# VPAC0_COMMON_0_PAR_VPAC_VISS0_S_VBUSP_K3_GLBCE_TOP_CFG_GLBCE register map
Vendor: Texas Instruments
Peripheral module from a debugger description file (folder J7_AHP).
Registers are 32-bit, read-write, reset 0x0 unless marked. A register's access mark holds for its fields unless they carry their own. Offsets are as the file gives them; lines under a group give offsets from that group; [hi:lo] are bit positions; {n}, {i} and the like mark numbered series; 'fields as' and 'values as' point back to an identical list; <NAME> marks a mode.

## VPAC0_COMMON_0_PAR_VPAC_VISS0_S_VBUSP_K3_GLBCE_TOP_CFG_GLBCE (part 1 of 2)
0x328 PAR_VPAC_VISS0__S_VBUSP__K3_GLBCE_TOP__CFG__GLBCE_REGS_GLBCE_WDR_GAMMA_LUT_21 reset 0x1500
  [15:0] VAL — LUT Value
0x32C PAR_VPAC_VISS0__S_VBUSP__K3_GLBCE_TOP__CFG__GLBCE_REGS_GLBCE_WDR_GAMMA_LUT_22 reset 0x1600
  [15:0] VAL — LUT Value
0x330 PAR_VPAC_VISS0__S_VBUSP__K3_GLBCE_TOP__CFG__GLBCE_REGS_GLBCE_WDR_GAMMA_LUT_23 reset 0x1700
  [15:0] VAL — LUT Value
0x334 PAR_VPAC_VISS0__S_VBUSP__K3_GLBCE_TOP__CFG__GLBCE_REGS_GLBCE_WDR_GAMMA_LUT_24 reset 0x1800
  [15:0] VAL — LUT Value
0x338 PAR_VPAC_VISS0__S_VBUSP__K3_GLBCE_TOP__CFG__GLBCE_REGS_GLBCE_WDR_GAMMA_LUT_25 reset 0x1900
  [15:0] VAL — LUT Value
0x33C PAR_VPAC_VISS0__S_VBUSP__K3_GLBCE_TOP__CFG__GLBCE_REGS_GLBCE_WDR_GAMMA_LUT_26 reset 0x1A00
  [15:0] VAL — LUT Value
0x340 PAR_VPAC_VISS0__S_VBUSP__K3_GLBCE_TOP__CFG__GLBCE_REGS_GLBCE_WDR_GAMMA_LUT_27 reset 0x1B00
  [15:0] VAL — LUT Value
0x344 PAR_VPAC_VISS0__S_VBUSP__K3_GLBCE_TOP__CFG__GLBCE_REGS_GLBCE_WDR_GAMMA_LUT_28 reset 0x1C00
  [15:0] VAL — LUT Value
0x348 PAR_VPAC_VISS0__S_VBUSP__K3_GLBCE_TOP__CFG__GLBCE_REGS_GLBCE_WDR_GAMMA_LUT_29 reset 0x1D00
  [15:0] VAL — LUT Value
0x34C PAR_VPAC_VISS0__S_VBUSP__K3_GLBCE_TOP__CFG__GLBCE_REGS_GLBCE_WDR_GAMMA_LUT_30 reset 0x1E00
  [15:0] VAL — LUT Value
0x350 PAR_VPAC_VISS0__S_VBUSP__K3_GLBCE_TOP__CFG__GLBCE_REGS_GLBCE_WDR_GAMMA_LUT_31 reset 0x1F00
  [15:0] VAL — LUT Value
0x354 PAR_VPAC_VISS0__S_VBUSP__K3_GLBCE_TOP__CFG__GLBCE_REGS_GLBCE_WDR_GAMMA_LUT_32 reset 0x2000
  [15:0] VAL — LUT Value
0x358 PAR_VPAC_VISS0__S_VBUSP__K3_GLBCE_TOP__CFG__GLBCE_REGS_GLBCE_WDR_GAMMA_LUT_33 reset 0x2100
  [15:0] VAL — LUT Value
0x35C PAR_VPAC_VISS0__S_VBUSP__K3_GLBCE_TOP__CFG__GLBCE_REGS_GLBCE_WDR_GAMMA_LUT_34 reset 0x2200
  [15:0] VAL — LUT Value
0x360 PAR_VPAC_VISS0__S_VBUSP__K3_GLBCE_TOP__CFG__GLBCE_REGS_GLBCE_WDR_GAMMA_LUT_35 reset 0x2300
  [15:0] VAL — LUT Value
0x364 PAR_VPAC_VISS0__S_VBUSP__K3_GLBCE_TOP__CFG__GLBCE_REGS_GLBCE_WDR_GAMMA_LUT_36 reset 0x2400
  [15:0] VAL — LUT Value
0x368 PAR_VPAC_VISS0__S_VBUSP__K3_GLBCE_TOP__CFG__GLBCE_REGS_GLBCE_WDR_GAMMA_LUT_37 reset 0x2500
  [15:0] VAL — LUT Value
0x36C PAR_VPAC_VISS0__S_VBUSP__K3_GLBCE_TOP__CFG__GLBCE_REGS_GLBCE_WDR_GAMMA_LUT_38 reset 0x2600
  [15:0] VAL — LUT Value
0x370 PAR_VPAC_VISS0__S_VBUSP__K3_GLBCE_TOP__CFG__GLBCE_REGS_GLBCE_WDR_GAMMA_LUT_39 reset 0x2700
  [15:0] VAL — LUT Value
0x374 PAR_VPAC_VISS0__S_VBUSP__K3_GLBCE_TOP__CFG__GLBCE_REGS_GLBCE_WDR_GAMMA_LUT_40 reset 0x2800
  [15:0] VAL — LUT Value
0x378 PAR_VPAC_VISS0__S_VBUSP__K3_GLBCE_TOP__CFG__GLBCE_REGS_GLBCE_WDR_GAMMA_LUT_41 reset 0x2900
  [15:0] VAL — LUT Value
0x37C PAR_VPAC_VISS0__S_VBUSP__K3_GLBCE_TOP__CFG__GLBCE_REGS_GLBCE_WDR_GAMMA_LUT_42 reset 0x2A00
  [15:0] VAL — LUT Value
0x380 PAR_VPAC_VISS0__S_VBUSP__K3_GLBCE_TOP__CFG__GLBCE_REGS_GLBCE_WDR_GAMMA_LUT_43 reset 0x2B00
  [15:0] VAL — LUT Value
0x384 PAR_VPAC_VISS0__S_VBUSP__K3_GLBCE_TOP__CFG__GLBCE_REGS_GLBCE_WDR_GAMMA_LUT_44 reset 0x2C00
  [15:0] VAL — LUT Value
0x388 PAR_VPAC_VISS0__S_VBUSP__K3_GLBCE_TOP__CFG__GLBCE_REGS_GLBCE_WDR_GAMMA_LUT_45 reset 0x2D00
  [15:0] VAL — LUT Value
0x38C PAR_VPAC_VISS0__S_VBUSP__K3_GLBCE_TOP__CFG__GLBCE_REGS_GLBCE_WDR_GAMMA_LUT_46 reset 0x2E00
  [15:0] VAL — LUT Value
0x390 PAR_VPAC_VISS0__S_VBUSP__K3_GLBCE_TOP__CFG__GLBCE_REGS_GLBCE_WDR_GAMMA_LUT_47 reset 0x2F00
  [15:0] VAL — LUT Value
0x394 PAR_VPAC_VISS0__S_VBUSP__K3_GLBCE_TOP__CFG__GLBCE_REGS_GLBCE_WDR_GAMMA_LUT_48 reset 0x3000
  [15:0] VAL — LUT Value
0x398 PAR_VPAC_VISS0__S_VBUSP__K3_GLBCE_TOP__CFG__GLBCE_REGS_GLBCE_WDR_GAMMA_LUT_49 reset 0x3100
  [15:0] VAL — LUT Value
0x39C PAR_VPAC_VISS0__S_VBUSP__K3_GLBCE_TOP__CFG__GLBCE_REGS_GLBCE_WDR_GAMMA_LUT_50 reset 0x3200
  [15:0] VAL — LUT Value
0x3A0 PAR_VPAC_VISS0__S_VBUSP__K3_GLBCE_TOP__CFG__GLBCE_REGS_GLBCE_WDR_GAMMA_LUT_51 reset 0x3300
  [15:0] VAL — LUT Value
0x3A4 PAR_VPAC_VISS0__S_VBUSP__K3_GLBCE_TOP__CFG__GLBCE_REGS_GLBCE_WDR_GAMMA_LUT_52 reset 0x3400
  [15:0] VAL — LUT Value
0x3A8 PAR_VPAC_VISS0__S_VBUSP__K3_GLBCE_TOP__CFG__GLBCE_REGS_GLBCE_WDR_GAMMA_LUT_53 reset 0x3500
  [15:0] VAL — LUT Value
0x3AC PAR_VPAC_VISS0__S_VBUSP__K3_GLBCE_TOP__CFG__GLBCE_REGS_GLBCE_WDR_GAMMA_LUT_54 reset 0x3600
  [15:0] VAL — LUT Value
0x3B0 PAR_VPAC_VISS0__S_VBUSP__K3_GLBCE_TOP__CFG__GLBCE_REGS_GLBCE_WDR_GAMMA_LUT_55 reset 0x3700
  [15:0] VAL — LUT Value
0x3B4 PAR_VPAC_VISS0__S_VBUSP__K3_GLBCE_TOP__CFG__GLBCE_REGS_GLBCE_WDR_GAMMA_LUT_56 reset 0x3800
  [15:0] VAL — LUT Value
0x3B8 PAR_VPAC_VISS0__S_VBUSP__K3_GLBCE_TOP__CFG__GLBCE_REGS_GLBCE_WDR_GAMMA_LUT_57 reset 0x3900
  [15:0] VAL — LUT Value
0x3BC PAR_VPAC_VISS0__S_VBUSP__K3_GLBCE_TOP__CFG__GLBCE_REGS_GLBCE_WDR_GAMMA_LUT_58 reset 0x3A00
  [15:0] VAL — LUT Value
0x3C0 PAR_VPAC_VISS0__S_VBUSP__K3_GLBCE_TOP__CFG__GLBCE_REGS_GLBCE_WDR_GAMMA_LUT_59 reset 0x3B00
  [15:0] VAL — LUT Value
0x3C4 PAR_VPAC_VISS0__S_VBUSP__K3_GLBCE_TOP__CFG__GLBCE_REGS_GLBCE_WDR_GAMMA_LUT_60 reset 0x3C00
  [15:0] VAL — LUT Value
0x3C8 PAR_VPAC_VISS0__S_VBUSP__K3_GLBCE_TOP__CFG__GLBCE_REGS_GLBCE_WDR_GAMMA_LUT_61 reset 0x3D00
  [15:0] VAL — LUT Value
0x3CC PAR_VPAC_VISS0__S_VBUSP__K3_GLBCE_TOP__CFG__GLBCE_REGS_GLBCE_WDR_GAMMA_LUT_62 reset 0x3E00
  [15:0] VAL — LUT Value
0x3D0 PAR_VPAC_VISS0__S_VBUSP__K3_GLBCE_TOP__CFG__GLBCE_REGS_GLBCE_WDR_GAMMA_LUT_63 reset 0x3F00
  [15:0] VAL — LUT Value
0x3D4 PAR_VPAC_VISS0__S_VBUSP__K3_GLBCE_TOP__CFG__GLBCE_REGS_GLBCE_WDR_GAMMA_LUT_64 reset 0x4000
  [15:0] VAL — LUT Value
0x3D8 PAR_VPAC_VISS0__S_VBUSP__K3_GLBCE_TOP__CFG__GLBCE_REGS_GLBCE_WDR_GAMMA_LUT_65 reset 0x4100
  [15:0] VAL — LUT Value
0x3DC PAR_VPAC_VISS0__S_VBUSP__K3_GLBCE_TOP__CFG__GLBCE_REGS_GLBCE_WDR_GAMMA_LUT_66 reset 0x4200
  [15:0] VAL — LUT Value
0x3E0 PAR_VPAC_VISS0__S_VBUSP__K3_GLBCE_TOP__CFG__GLBCE_REGS_GLBCE_WDR_GAMMA_LUT_67 reset 0x4300
  [15:0] VAL — LUT Value
0x3E4 PAR_VPAC_VISS0__S_VBUSP__K3_GLBCE_TOP__CFG__GLBCE_REGS_GLBCE_WDR_GAMMA_LUT_68 reset 0x4400
  [15:0] VAL — LUT Value
0x3E8 PAR_VPAC_VISS0__S_VBUSP__K3_GLBCE_TOP__CFG__GLBCE_REGS_GLBCE_WDR_GAMMA_LUT_69 reset 0x4500
  [15:0] VAL — LUT Value
0x3EC PAR_VPAC_VISS0__S_VBUSP__K3_GLBCE_TOP__CFG__GLBCE_REGS_GLBCE_WDR_GAMMA_LUT_70 reset 0x4600
  [15:0] VAL — LUT Value
0x3F0 PAR_VPAC_VISS0__S_VBUSP__K3_GLBCE_TOP__CFG__GLBCE_REGS_GLBCE_WDR_GAMMA_LUT_71 reset 0x4700
  [15:0] VAL — LUT Value
0x3F4 PAR_VPAC_VISS0__S_VBUSP__K3_GLBCE_TOP__CFG__GLBCE_REGS_GLBCE_WDR_GAMMA_LUT_72 reset 0x4800
  [15:0] VAL — LUT Value
0x3F8 PAR_VPAC_VISS0__S_VBUSP__K3_GLBCE_TOP__CFG__GLBCE_REGS_GLBCE_WDR_GAMMA_LUT_73 reset 0x4900
  [15:0] VAL — LUT Value
0x3FC PAR_VPAC_VISS0__S_VBUSP__K3_GLBCE_TOP__CFG__GLBCE_REGS_GLBCE_WDR_GAMMA_LUT_74 reset 0x4A00
  [15:0] VAL — LUT Value
0x400 PAR_VPAC_VISS0__S_VBUSP__K3_GLBCE_TOP__CFG__GLBCE_REGS_GLBCE_WDR_GAMMA_LUT_75 reset 0x4B00
  [15:0] VAL — LUT Value
0x404 PAR_VPAC_VISS0__S_VBUSP__K3_GLBCE_TOP__CFG__GLBCE_REGS_GLBCE_WDR_GAMMA_LUT_76 reset 0x4C00
  [15:0] VAL — LUT Value
0x408 PAR_VPAC_VISS0__S_VBUSP__K3_GLBCE_TOP__CFG__GLBCE_REGS_GLBCE_WDR_GAMMA_LUT_77 reset 0x4D00
  [15:0] VAL — LUT Value
0x40C PAR_VPAC_VISS0__S_VBUSP__K3_GLBCE_TOP__CFG__GLBCE_REGS_GLBCE_WDR_GAMMA_LUT_78 reset 0x4E00
  [15:0] VAL — LUT Value
0x410 PAR_VPAC_VISS0__S_VBUSP__K3_GLBCE_TOP__CFG__GLBCE_REGS_GLBCE_WDR_GAMMA_LUT_79 reset 0x4F00
  [15:0] VAL — LUT Value
0x414 PAR_VPAC_VISS0__S_VBUSP__K3_GLBCE_TOP__CFG__GLBCE_REGS_GLBCE_WDR_GAMMA_LUT_80 reset 0x5000
  [15:0] VAL — LUT Value
0x418 PAR_VPAC_VISS0__S_VBUSP__K3_GLBCE_TOP__CFG__GLBCE_REGS_GLBCE_WDR_GAMMA_LUT_81 reset 0x5100
  [15:0] VAL — LUT Value
0x41C PAR_VPAC_VISS0__S_VBUSP__K3_GLBCE_TOP__CFG__GLBCE_REGS_GLBCE_WDR_GAMMA_LUT_82 reset 0x5200
  [15:0] VAL — LUT Value
0x420 PAR_VPAC_VISS0__S_VBUSP__K3_GLBCE_TOP__CFG__GLBCE_REGS_GLBCE_WDR_GAMMA_LUT_83 reset 0x5300
  [15:0] VAL — LUT Value
0x424 PAR_VPAC_VISS0__S_VBUSP__K3_GLBCE_TOP__CFG__GLBCE_REGS_GLBCE_WDR_GAMMA_LUT_84 reset 0x5400
  [15:0] VAL — LUT Value
0x428 PAR_VPAC_VISS0__S_VBUSP__K3_GLBCE_TOP__CFG__GLBCE_REGS_GLBCE_WDR_GAMMA_LUT_85 reset 0x5500
  [15:0] VAL — LUT Value
0x42C PAR_VPAC_VISS0__S_VBUSP__K3_GLBCE_TOP__CFG__GLBCE_REGS_GLBCE_WDR_GAMMA_LUT_86 reset 0x5600
  [15:0] VAL — LUT Value
0x430 PAR_VPAC_VISS0__S_VBUSP__K3_GLBCE_TOP__CFG__GLBCE_REGS_GLBCE_WDR_GAMMA_LUT_87 reset 0x5700
  [15:0] VAL — LUT Value
0x434 PAR_VPAC_VISS0__S_VBUSP__K3_GLBCE_TOP__CFG__GLBCE_REGS_GLBCE_WDR_GAMMA_LUT_88 reset 0x5800
  [15:0] VAL — LUT Value
0x438 PAR_VPAC_VISS0__S_VBUSP__K3_GLBCE_TOP__CFG__GLBCE_REGS_GLBCE_WDR_GAMMA_LUT_89 reset 0x5900
  [15:0] VAL — LUT Value
0x43C PAR_VPAC_VISS0__S_VBUSP__K3_GLBCE_TOP__CFG__GLBCE_REGS_GLBCE_WDR_GAMMA_LUT_90 reset 0x5A00
  [15:0] VAL — LUT Value
0x440 PAR_VPAC_VISS0__S_VBUSP__K3_GLBCE_TOP__CFG__GLBCE_REGS_GLBCE_WDR_GAMMA_LUT_91 reset 0x5B00
  [15:0] VAL — LUT Value
0x444 PAR_VPAC_VISS0__S_VBUSP__K3_GLBCE_TOP__CFG__GLBCE_REGS_GLBCE_WDR_GAMMA_LUT_92 reset 0x5C00
  [15:0] VAL — LUT Value
0x448 PAR_VPAC_VISS0__S_VBUSP__K3_GLBCE_TOP__CFG__GLBCE_REGS_GLBCE_WDR_GAMMA_LUT_93 reset 0x5D00
  [15:0] VAL — LUT Value
0x44C PAR_VPAC_VISS0__S_VBUSP__K3_GLBCE_TOP__CFG__GLBCE_REGS_GLBCE_WDR_GAMMA_LUT_94 reset 0x5E00
  [15:0] VAL — LUT Value
0x450 PAR_VPAC_VISS0__S_VBUSP__K3_GLBCE_TOP__CFG__GLBCE_REGS_GLBCE_WDR_GAMMA_LUT_95 reset 0x5F00
  [15:0] VAL — LUT Value
0x454 PAR_VPAC_VISS0__S_VBUSP__K3_GLBCE_TOP__CFG__GLBCE_REGS_GLBCE_WDR_GAMMA_LUT_96 reset 0x6000
  [15:0] VAL — LUT Value
0x458 PAR_VPAC_VISS0__S_VBUSP__K3_GLBCE_TOP__CFG__GLBCE_REGS_GLBCE_WDR_GAMMA_LUT_97 reset 0x6100
  [15:0] VAL — LUT Value
0x45C PAR_VPAC_VISS0__S_VBUSP__K3_GLBCE_TOP__CFG__GLBCE_REGS_GLBCE_WDR_GAMMA_LUT_98 reset 0x6200
  [15:0] VAL — LUT Value
0x460 PAR_VPAC_VISS0__S_VBUSP__K3_GLBCE_TOP__CFG__GLBCE_REGS_GLBCE_WDR_GAMMA_LUT_99 reset 0x6300
  [15:0] VAL — LUT Value
0x464 PAR_VPAC_VISS0__S_VBUSP__K3_GLBCE_TOP__CFG__GLBCE_REGS_GLBCE_WDR_GAMMA_LUT_100 reset 0x6400
  [15:0] VAL — LUT Value
0x468 PAR_VPAC_VISS0__S_VBUSP__K3_GLBCE_TOP__CFG__GLBCE_REGS_GLBCE_WDR_GAMMA_LUT_101 reset 0x6500
  [15:0] VAL — LUT Value
0x46C PAR_VPAC_VISS0__S_VBUSP__K3_GLBCE_TOP__CFG__GLBCE_REGS_GLBCE_WDR_GAMMA_LUT_102 reset 0x6600
  [15:0] VAL — LUT Value
0x470 PAR_VPAC_VISS0__S_VBUSP__K3_GLBCE_TOP__CFG__GLBCE_REGS_GLBCE_WDR_GAMMA_LUT_103 reset 0x6700
  [15:0] VAL — LUT Value
0x474 PAR_VPAC_VISS0__S_VBUSP__K3_GLBCE_TOP__CFG__GLBCE_REGS_GLBCE_WDR_GAMMA_LUT_104 reset 0x6800
  [15:0] VAL — LUT Value
0x478 PAR_VPAC_VISS0__S_VBUSP__K3_GLBCE_TOP__CFG__GLBCE_REGS_GLBCE_WDR_GAMMA_LUT_105 reset 0x6900
  [15:0] VAL — LUT Value
0x47C PAR_VPAC_VISS0__S_VBUSP__K3_GLBCE_TOP__CFG__GLBCE_REGS_GLBCE_WDR_GAMMA_LUT_106 reset 0x6A00
  [15:0] VAL — LUT Value
0x480 PAR_VPAC_VISS0__S_VBUSP__K3_GLBCE_TOP__CFG__GLBCE_REGS_GLBCE_WDR_GAMMA_LUT_107 reset 0x6B00
  [15:0] VAL — LUT Value
0x484 PAR_VPAC_VISS0__S_VBUSP__K3_GLBCE_TOP__CFG__GLBCE_REGS_GLBCE_WDR_GAMMA_LUT_108 reset 0x6C00
  [15:0] VAL — LUT Value
0x488 PAR_VPAC_VISS0__S_VBUSP__K3_GLBCE_TOP__CFG__GLBCE_REGS_GLBCE_WDR_GAMMA_LUT_109 reset 0x6D00
  [15:0] VAL — LUT Value
0x48C PAR_VPAC_VISS0__S_VBUSP__K3_GLBCE_TOP__CFG__GLBCE_REGS_GLBCE_WDR_GAMMA_LUT_110 reset 0x6E00
  [15:0] VAL — LUT Value
0x490 PAR_VPAC_VISS0__S_VBUSP__K3_GLBCE_TOP__CFG__GLBCE_REGS_GLBCE_WDR_GAMMA_LUT_111 reset 0x6F00
  [15:0] VAL — LUT Value
0x494 PAR_VPAC_VISS0__S_VBUSP__K3_GLBCE_TOP__CFG__GLBCE_REGS_GLBCE_WDR_GAMMA_LUT_112 reset 0x7000
  [15:0] VAL — LUT Value
0x498 PAR_VPAC_VISS0__S_VBUSP__K3_GLBCE_TOP__CFG__GLBCE_REGS_GLBCE_WDR_GAMMA_LUT_113 reset 0x7100
  [15:0] VAL — LUT Value
0x49C PAR_VPAC_VISS0__S_VBUSP__K3_GLBCE_TOP__CFG__GLBCE_REGS_GLBCE_WDR_GAMMA_LUT_114 reset 0x7200
  [15:0] VAL — LUT Value
0x4A0 PAR_VPAC_VISS0__S_VBUSP__K3_GLBCE_TOP__CFG__GLBCE_REGS_GLBCE_WDR_GAMMA_LUT_115 reset 0x7300
  [15:0] VAL — LUT Value
0x4A4 PAR_VPAC_VISS0__S_VBUSP__K3_GLBCE_TOP__CFG__GLBCE_REGS_GLBCE_WDR_GAMMA_LUT_116 reset 0x7400
  [15:0] VAL — LUT Value
0x4A8 PAR_VPAC_VISS0__S_VBUSP__K3_GLBCE_TOP__CFG__GLBCE_REGS_GLBCE_WDR_GAMMA_LUT_117 reset 0x7500
  [15:0] VAL — LUT Value
0x4AC PAR_VPAC_VISS0__S_VBUSP__K3_GLBCE_TOP__CFG__GLBCE_REGS_GLBCE_WDR_GAMMA_LUT_118 reset 0x7600
  [15:0] VAL — LUT Value
0x4B0 PAR_VPAC_VISS0__S_VBUSP__K3_GLBCE_TOP__CFG__GLBCE_REGS_GLBCE_WDR_GAMMA_LUT_119 reset 0x7700
  [15:0] VAL — LUT Value
0x4B4 PAR_VPAC_VISS0__S_VBUSP__K3_GLBCE_TOP__CFG__GLBCE_REGS_GLBCE_WDR_GAMMA_LUT_120 reset 0x7800
  [15:0] VAL — LUT Value
0x4B8 PAR_VPAC_VISS0__S_VBUSP__K3_GLBCE_TOP__CFG__GLBCE_REGS_GLBCE_WDR_GAMMA_LUT_121 reset 0x7900
  [15:0] VAL — LUT Value
0x4BC PAR_VPAC_VISS0__S_VBUSP__K3_GLBCE_TOP__CFG__GLBCE_REGS_GLBCE_WDR_GAMMA_LUT_122 reset 0x7A00
  [15:0] VAL — LUT Value
0x4C0 PAR_VPAC_VISS0__S_VBUSP__K3_GLBCE_TOP__CFG__GLBCE_REGS_GLBCE_WDR_GAMMA_LUT_123 reset 0x7B00
  [15:0] VAL — LUT Value
0x4C4 PAR_VPAC_VISS0__S_VBUSP__K3_GLBCE_TOP__CFG__GLBCE_REGS_GLBCE_WDR_GAMMA_LUT_124 reset 0x7C00
  [15:0] VAL — LUT Value
0x4C8 PAR_VPAC_VISS0__S_VBUSP__K3_GLBCE_TOP__CFG__GLBCE_REGS_GLBCE_WDR_GAMMA_LUT_125 reset 0x7D00
  [15:0] VAL — LUT Value
0x4CC PAR_VPAC_VISS0__S_VBUSP__K3_GLBCE_TOP__CFG__GLBCE_REGS_GLBCE_WDR_GAMMA_LUT_126 reset 0x7E00
  [15:0] VAL — LUT Value
0x4D0 PAR_VPAC_VISS0__S_VBUSP__K3_GLBCE_TOP__CFG__GLBCE_REGS_GLBCE_WDR_GAMMA_LUT_127 reset 0x7F00
  [15:0] VAL — LUT Value
0x4D4 PAR_VPAC_VISS0__S_VBUSP__K3_GLBCE_TOP__CFG__GLBCE_REGS_GLBCE_WDR_GAMMA_LUT_128 reset 0x8000
  [15:0] VAL — LUT Value
0x4D8 PAR_VPAC_VISS0__S_VBUSP__K3_GLBCE_TOP__CFG__GLBCE_REGS_GLBCE_WDR_GAMMA_LUT_129 reset 0x8100
  [15:0] VAL — LUT Value
0x4DC PAR_VPAC_VISS0__S_VBUSP__K3_GLBCE_TOP__CFG__GLBCE_REGS_GLBCE_WDR_GAMMA_LUT_130 reset 0x8200
  [15:0] VAL — LUT Value
0x4E0 PAR_VPAC_VISS0__S_VBUSP__K3_GLBCE_TOP__CFG__GLBCE_REGS_GLBCE_WDR_GAMMA_LUT_131 reset 0x8300
  [15:0] VAL — LUT Value
0x4E4 PAR_VPAC_VISS0__S_VBUSP__K3_GLBCE_TOP__CFG__GLBCE_REGS_GLBCE_WDR_GAMMA_LUT_132 reset 0x8400
  [15:0] VAL — LUT Value
0x4E8 PAR_VPAC_VISS0__S_VBUSP__K3_GLBCE_TOP__CFG__GLBCE_REGS_GLBCE_WDR_GAMMA_LUT_133 reset 0x8500
  [15:0] VAL — LUT Value
0x4EC PAR_VPAC_VISS0__S_VBUSP__K3_GLBCE_TOP__CFG__GLBCE_REGS_GLBCE_WDR_GAMMA_LUT_134 reset 0x8600
  [15:0] VAL — LUT Value
0x4F0 PAR_VPAC_VISS0__S_VBUSP__K3_GLBCE_TOP__CFG__GLBCE_REGS_GLBCE_WDR_GAMMA_LUT_135 reset 0x8700
  [15:0] VAL — LUT Value
0x4F4 PAR_VPAC_VISS0__S_VBUSP__K3_GLBCE_TOP__CFG__GLBCE_REGS_GLBCE_WDR_GAMMA_LUT_136 reset 0x8800
  [15:0] VAL — LUT Value
0x4F8 PAR_VPAC_VISS0__S_VBUSP__K3_GLBCE_TOP__CFG__GLBCE_REGS_GLBCE_WDR_GAMMA_LUT_137 reset 0x8900
  [15:0] VAL — LUT Value
0x4FC PAR_VPAC_VISS0__S_VBUSP__K3_GLBCE_TOP__CFG__GLBCE_REGS_GLBCE_WDR_GAMMA_LUT_138 reset 0x8A00
  [15:0] VAL — LUT Value
0x500 PAR_VPAC_VISS0__S_VBUSP__K3_GLBCE_TOP__CFG__GLBCE_REGS_GLBCE_WDR_GAMMA_LUT_139 reset 0x8B00
  [15:0] VAL — LUT Value
0x504 PAR_VPAC_VISS0__S_VBUSP__K3_GLBCE_TOP__CFG__GLBCE_REGS_GLBCE_WDR_GAMMA_LUT_140 reset 0x8C00
  [15:0] VAL — LUT Value
0x508 PAR_VPAC_VISS0__S_VBUSP__K3_GLBCE_TOP__CFG__GLBCE_REGS_GLBCE_WDR_GAMMA_LUT_141 reset 0x8D00
  [15:0] VAL — LUT Value
0x50C PAR_VPAC_VISS0__S_VBUSP__K3_GLBCE_TOP__CFG__GLBCE_REGS_GLBCE_WDR_GAMMA_LUT_142 reset 0x8E00
  [15:0] VAL — LUT Value
0x510 PAR_VPAC_VISS0__S_VBUSP__K3_GLBCE_TOP__CFG__GLBCE_REGS_GLBCE_WDR_GAMMA_LUT_143 reset 0x8F00
  [15:0] VAL — LUT Value
0x514 PAR_VPAC_VISS0__S_VBUSP__K3_GLBCE_TOP__CFG__GLBCE_REGS_GLBCE_WDR_GAMMA_LUT_144 reset 0x9000
  [15:0] VAL — LUT Value
0x518 PAR_VPAC_VISS0__S_VBUSP__K3_GLBCE_TOP__CFG__GLBCE_REGS_GLBCE_WDR_GAMMA_LUT_145 reset 0x9100
  [15:0] VAL — LUT Value
0x51C PAR_VPAC_VISS0__S_VBUSP__K3_GLBCE_TOP__CFG__GLBCE_REGS_GLBCE_WDR_GAMMA_LUT_146 reset 0x9200
  [15:0] VAL — LUT Value
0x520 PAR_VPAC_VISS0__S_VBUSP__K3_GLBCE_TOP__CFG__GLBCE_REGS_GLBCE_WDR_GAMMA_LUT_147 reset 0x9300
  [15:0] VAL — LUT Value
0x524 PAR_VPAC_VISS0__S_VBUSP__K3_GLBCE_TOP__CFG__GLBCE_REGS_GLBCE_WDR_GAMMA_LUT_148 reset 0x9400
  [15:0] VAL — LUT Value
0x528 PAR_VPAC_VISS0__S_VBUSP__K3_GLBCE_TOP__CFG__GLBCE_REGS_GLBCE_WDR_GAMMA_LUT_149 reset 0x9500
  [15:0] VAL — LUT Value
0x52C PAR_VPAC_VISS0__S_VBUSP__K3_GLBCE_TOP__CFG__GLBCE_REGS_GLBCE_WDR_GAMMA_LUT_150 reset 0x9600
  [15:0] VAL — LUT Value
0x530 PAR_VPAC_VISS0__S_VBUSP__K3_GLBCE_TOP__CFG__GLBCE_REGS_GLBCE_WDR_GAMMA_LUT_151 reset 0x9700
  [15:0] VAL — LUT Value
0x534 PAR_VPAC_VISS0__S_VBUSP__K3_GLBCE_TOP__CFG__GLBCE_REGS_GLBCE_WDR_GAMMA_LUT_152 reset 0x9800
  [15:0] VAL — LUT Value
0x538 PAR_VPAC_VISS0__S_VBUSP__K3_GLBCE_TOP__CFG__GLBCE_REGS_GLBCE_WDR_GAMMA_LUT_153 reset 0x9900
  [15:0] VAL — LUT Value
0x53C PAR_VPAC_VISS0__S_VBUSP__K3_GLBCE_TOP__CFG__GLBCE_REGS_GLBCE_WDR_GAMMA_LUT_154 reset 0x9A00
  [15:0] VAL — LUT Value
0x540 PAR_VPAC_VISS0__S_VBUSP__K3_GLBCE_TOP__CFG__GLBCE_REGS_GLBCE_WDR_GAMMA_LUT_155 reset 0x9B00
  [15:0] VAL — LUT Value
0x544 PAR_VPAC_VISS0__S_VBUSP__K3_GLBCE_TOP__CFG__GLBCE_REGS_GLBCE_WDR_GAMMA_LUT_156 reset 0x9C00
  [15:0] VAL — LUT Value
0x548 PAR_VPAC_VISS0__S_VBUSP__K3_GLBCE_TOP__CFG__GLBCE_REGS_GLBCE_WDR_GAMMA_LUT_157 reset 0x9D00
  [15:0] VAL — LUT Value
0x54C PAR_VPAC_VISS0__S_VBUSP__K3_GLBCE_TOP__CFG__GLBCE_REGS_GLBCE_WDR_GAMMA_LUT_158 reset 0x9E00
  [15:0] VAL — LUT Value
0x550 PAR_VPAC_VISS0__S_VBUSP__K3_GLBCE_TOP__CFG__GLBCE_REGS_GLBCE_WDR_GAMMA_LUT_159 reset 0x9F00
  [15:0] VAL — LUT Value
0x554 PAR_VPAC_VISS0__S_VBUSP__K3_GLBCE_TOP__CFG__GLBCE_REGS_GLBCE_WDR_GAMMA_LUT_160 reset 0xA000
  [15:0] VAL — LUT Value
0x558 PAR_VPAC_VISS0__S_VBUSP__K3_GLBCE_TOP__CFG__GLBCE_REGS_GLBCE_WDR_GAMMA_LUT_161 reset 0xA100
  [15:0] VAL — LUT Value
0x55C PAR_VPAC_VISS0__S_VBUSP__K3_GLBCE_TOP__CFG__GLBCE_REGS_GLBCE_WDR_GAMMA_LUT_162 reset 0xA200
  [15:0] VAL — LUT Value
0x560 PAR_VPAC_VISS0__S_VBUSP__K3_GLBCE_TOP__CFG__GLBCE_REGS_GLBCE_WDR_GAMMA_LUT_163 reset 0xA300
  [15:0] VAL — LUT Value
0x564 PAR_VPAC_VISS0__S_VBUSP__K3_GLBCE_TOP__CFG__GLBCE_REGS_GLBCE_WDR_GAMMA_LUT_164 reset 0xA400
  [15:0] VAL — LUT Value
0x568 PAR_VPAC_VISS0__S_VBUSP__K3_GLBCE_TOP__CFG__GLBCE_REGS_GLBCE_WDR_GAMMA_LUT_165 reset 0xA500
  [15:0] VAL — LUT Value
0x56C PAR_VPAC_VISS0__S_VBUSP__K3_GLBCE_TOP__CFG__GLBCE_REGS_GLBCE_WDR_GAMMA_LUT_166 reset 0xA600
  [15:0] VAL — LUT Value
0x570 PAR_VPAC_VISS0__S_VBUSP__K3_GLBCE_TOP__CFG__GLBCE_REGS_GLBCE_WDR_GAMMA_LUT_167 reset 0xA700
  [15:0] VAL — LUT Value
0x574 PAR_VPAC_VISS0__S_VBUSP__K3_GLBCE_TOP__CFG__GLBCE_REGS_GLBCE_WDR_GAMMA_LUT_168 reset 0xA800
  [15:0] VAL — LUT Value
0x578 PAR_VPAC_VISS0__S_VBUSP__K3_GLBCE_TOP__CFG__GLBCE_REGS_GLBCE_WDR_GAMMA_LUT_169 reset 0xA900
  [15:0] VAL — LUT Value
0x57C PAR_VPAC_VISS0__S_VBUSP__K3_GLBCE_TOP__CFG__GLBCE_REGS_GLBCE_WDR_GAMMA_LUT_170 reset 0xAA00
  [15:0] VAL — LUT Value
0x580 PAR_VPAC_VISS0__S_VBUSP__K3_GLBCE_TOP__CFG__GLBCE_REGS_GLBCE_WDR_GAMMA_LUT_171 reset 0xAB00
  [15:0] VAL — LUT Value
0x584 PAR_VPAC_VISS0__S_VBUSP__K3_GLBCE_TOP__CFG__GLBCE_REGS_GLBCE_WDR_GAMMA_LUT_172 reset 0xAC00
  [15:0] VAL — LUT Value
0x588 PAR_VPAC_VISS0__S_VBUSP__K3_GLBCE_TOP__CFG__GLBCE_REGS_GLBCE_WDR_GAMMA_LUT_173 reset 0xAD00
  [15:0] VAL — LUT Value
0x58C PAR_VPAC_VISS0__S_VBUSP__K3_GLBCE_TOP__CFG__GLBCE_REGS_GLBCE_WDR_GAMMA_LUT_174 reset 0xAE00
  [15:0] VAL — LUT Value
0x590 PAR_VPAC_VISS0__S_VBUSP__K3_GLBCE_TOP__CFG__GLBCE_REGS_GLBCE_WDR_GAMMA_LUT_175 reset 0xAF00
  [15:0] VAL — LUT Value
0x594 PAR_VPAC_VISS0__S_VBUSP__K3_GLBCE_TOP__CFG__GLBCE_REGS_GLBCE_WDR_GAMMA_LUT_176 reset 0xB000
  [15:0] VAL — LUT Value
0x598 PAR_VPAC_VISS0__S_VBUSP__K3_GLBCE_TOP__CFG__GLBCE_REGS_GLBCE_WDR_GAMMA_LUT_177 reset 0xB100
  [15:0] VAL — LUT Value
0x59C PAR_VPAC_VISS0__S_VBUSP__K3_GLBCE_TOP__CFG__GLBCE_REGS_GLBCE_WDR_GAMMA_LUT_178 reset 0xB200
  [15:0] VAL — LUT Value
0x5A0 PAR_VPAC_VISS0__S_VBUSP__K3_GLBCE_TOP__CFG__GLBCE_REGS_GLBCE_WDR_GAMMA_LUT_179 reset 0xB300
  [15:0] VAL — LUT Value
0x5A4 PAR_VPAC_VISS0__S_VBUSP__K3_GLBCE_TOP__CFG__GLBCE_REGS_GLBCE_WDR_GAMMA_LUT_180 reset 0xB400
  [15:0] VAL — LUT Value
0x5A8 PAR_VPAC_VISS0__S_VBUSP__K3_GLBCE_TOP__CFG__GLBCE_REGS_GLBCE_WDR_GAMMA_LUT_181 reset 0xB500
  [15:0] VAL — LUT Value
0x5AC PAR_VPAC_VISS0__S_VBUSP__K3_GLBCE_TOP__CFG__GLBCE_REGS_GLBCE_WDR_GAMMA_LUT_182 reset 0xB600
  [15:0] VAL — LUT Value
0x5B0 PAR_VPAC_VISS0__S_VBUSP__K3_GLBCE_TOP__CFG__GLBCE_REGS_GLBCE_WDR_GAMMA_LUT_183 reset 0xB700
  [15:0] VAL — LUT Value
0x5B4 PAR_VPAC_VISS0__S_VBUSP__K3_GLBCE_TOP__CFG__GLBCE_REGS_GLBCE_WDR_GAMMA_LUT_184 reset 0xB800
  [15:0] VAL — LUT Value
0x5B8 PAR_VPAC_VISS0__S_VBUSP__K3_GLBCE_TOP__CFG__GLBCE_REGS_GLBCE_WDR_GAMMA_LUT_185 reset 0xB900
  [15:0] VAL — LUT Value
0x5BC PAR_VPAC_VISS0__S_VBUSP__K3_GLBCE_TOP__CFG__GLBCE_REGS_GLBCE_WDR_GAMMA_LUT_186 reset 0xBA00
  [15:0] VAL — LUT Value
0x5C0 PAR_VPAC_VISS0__S_VBUSP__K3_GLBCE_TOP__CFG__GLBCE_REGS_GLBCE_WDR_GAMMA_LUT_187 reset 0xBB00
  [15:0] VAL — LUT Value
0x5C4 PAR_VPAC_VISS0__S_VBUSP__K3_GLBCE_TOP__CFG__GLBCE_REGS_GLBCE_WDR_GAMMA_LUT_188 reset 0xBC00
  [15:0] VAL — LUT Value
0x5C8 PAR_VPAC_VISS0__S_VBUSP__K3_GLBCE_TOP__CFG__GLBCE_REGS_GLBCE_WDR_GAMMA_LUT_189 reset 0xBD00
  [15:0] VAL — LUT Value
0x5CC PAR_VPAC_VISS0__S_VBUSP__K3_GLBCE_TOP__CFG__GLBCE_REGS_GLBCE_WDR_GAMMA_LUT_190 reset 0xBE00
  [15:0] VAL — LUT Value
0x5D0 PAR_VPAC_VISS0__S_VBUSP__K3_GLBCE_TOP__CFG__GLBCE_REGS_GLBCE_WDR_GAMMA_LUT_191 reset 0xBF00
  [15:0] VAL — LUT Value
0x5D4 PAR_VPAC_VISS0__S_VBUSP__K3_GLBCE_TOP__CFG__GLBCE_REGS_GLBCE_WDR_GAMMA_LUT_192 reset 0xC000
  [15:0] VAL — LUT Value
0x5D8 PAR_VPAC_VISS0__S_VBUSP__K3_GLBCE_TOP__CFG__GLBCE_REGS_GLBCE_WDR_GAMMA_LUT_193 reset 0xC100
  [15:0] VAL — LUT Value
0x5DC PAR_VPAC_VISS0__S_VBUSP__K3_GLBCE_TOP__CFG__GLBCE_REGS_GLBCE_WDR_GAMMA_LUT_194 reset 0xC200
  [15:0] VAL — LUT Value
0x5E0 PAR_VPAC_VISS0__S_VBUSP__K3_GLBCE_TOP__CFG__GLBCE_REGS_GLBCE_WDR_GAMMA_LUT_195 reset 0xC300
  [15:0] VAL — LUT Value
0x5E4 PAR_VPAC_VISS0__S_VBUSP__K3_GLBCE_TOP__CFG__GLBCE_REGS_GLBCE_WDR_GAMMA_LUT_196 reset 0xC400
  [15:0] VAL — LUT Value
0x5E8 PAR_VPAC_VISS0__S_VBUSP__K3_GLBCE_TOP__CFG__GLBCE_REGS_GLBCE_WDR_GAMMA_LUT_197 reset 0xC500
  [15:0] VAL — LUT Value
0x5EC PAR_VPAC_VISS0__S_VBUSP__K3_GLBCE_TOP__CFG__GLBCE_REGS_GLBCE_WDR_GAMMA_LUT_198 reset 0xC600
  [15:0] VAL — LUT Value
0x5F0 PAR_VPAC_VISS0__S_VBUSP__K3_GLBCE_TOP__CFG__GLBCE_REGS_GLBCE_WDR_GAMMA_LUT_199 reset 0xC700
  [15:0] VAL — LUT Value
0x5F4 PAR_VPAC_VISS0__S_VBUSP__K3_GLBCE_TOP__CFG__GLBCE_REGS_GLBCE_WDR_GAMMA_LUT_200 reset 0xC800
  [15:0] VAL — LUT Value
0x5F8 PAR_VPAC_VISS0__S_VBUSP__K3_GLBCE_TOP__CFG__GLBCE_REGS_GLBCE_WDR_GAMMA_LUT_201 reset 0xC900
  [15:0] VAL — LUT Value
0x5FC PAR_VPAC_VISS0__S_VBUSP__K3_GLBCE_TOP__CFG__GLBCE_REGS_GLBCE_WDR_GAMMA_LUT_202 reset 0xCA00
  [15:0] VAL — LUT Value
0x600 PAR_VPAC_VISS0__S_VBUSP__K3_GLBCE_TOP__CFG__GLBCE_REGS_GLBCE_WDR_GAMMA_LUT_203 reset 0xCB00
  [15:0] VAL — LUT Value
0x604 PAR_VPAC_VISS0__S_VBUSP__K3_GLBCE_TOP__CFG__GLBCE_REGS_GLBCE_WDR_GAMMA_LUT_204 reset 0xCC00
  [15:0] VAL — LUT Value
0x608 PAR_VPAC_VISS0__S_VBUSP__K3_GLBCE_TOP__CFG__GLBCE_REGS_GLBCE_WDR_GAMMA_LUT_205 reset 0xCD00
  [15:0] VAL — LUT Value
0x60C PAR_VPAC_VISS0__S_VBUSP__K3_GLBCE_TOP__CFG__GLBCE_REGS_GLBCE_WDR_GAMMA_LUT_206 reset 0xCE00
  [15:0] VAL — LUT Value
0x610 PAR_VPAC_VISS0__S_VBUSP__K3_GLBCE_TOP__CFG__GLBCE_REGS_GLBCE_WDR_GAMMA_LUT_207 reset 0xCF00
  [15:0] VAL — LUT Value
0x614 PAR_VPAC_VISS0__S_VBUSP__K3_GLBCE_TOP__CFG__GLBCE_REGS_GLBCE_WDR_GAMMA_LUT_208 reset 0xD000
  [15:0] VAL — LUT Value
0x618 PAR_VPAC_VISS0__S_VBUSP__K3_GLBCE_TOP__CFG__GLBCE_REGS_GLBCE_WDR_GAMMA_LUT_209 reset 0xD100
  [15:0] VAL — LUT Value
0x61C PAR_VPAC_VISS0__S_VBUSP__K3_GLBCE_TOP__CFG__GLBCE_REGS_GLBCE_WDR_GAMMA_LUT_210 reset 0xD200
  [15:0] VAL — LUT Value
0x620 PAR_VPAC_VISS0__S_VBUSP__K3_GLBCE_TOP__CFG__GLBCE_REGS_GLBCE_WDR_GAMMA_LUT_211 reset 0xD300
  [15:0] VAL — LUT Value
0x624 PAR_VPAC_VISS0__S_VBUSP__K3_GLBCE_TOP__CFG__GLBCE_REGS_GLBCE_WDR_GAMMA_LUT_212 reset 0xD400
  [15:0] VAL — LUT Value
0x628 PAR_VPAC_VISS0__S_VBUSP__K3_GLBCE_TOP__CFG__GLBCE_REGS_GLBCE_WDR_GAMMA_LUT_213 reset 0xD500
  [15:0] VAL — LUT Value
0x62C PAR_VPAC_VISS0__S_VBUSP__K3_GLBCE_TOP__CFG__GLBCE_REGS_GLBCE_WDR_GAMMA_LUT_214 reset 0xD600
  [15:0] VAL — LUT Value
0x630 PAR_VPAC_VISS0__S_VBUSP__K3_GLBCE_TOP__CFG__GLBCE_REGS_GLBCE_WDR_GAMMA_LUT_215 reset 0xD700
  [15:0] VAL — LUT Value
0x634 PAR_VPAC_VISS0__S_VBUSP__K3_GLBCE_TOP__CFG__GLBCE_REGS_GLBCE_WDR_GAMMA_LUT_216 reset 0xD800
  [15:0] VAL — LUT Value
0x638 PAR_VPAC_VISS0__S_VBUSP__K3_GLBCE_TOP__CFG__GLBCE_REGS_GLBCE_WDR_GAMMA_LUT_217 reset 0xD900
  [15:0] VAL — LUT Value
0x63C PAR_VPAC_VISS0__S_VBUSP__K3_GLBCE_TOP__CFG__GLBCE_REGS_GLBCE_WDR_GAMMA_LUT_218 reset 0xDA00
  [15:0] VAL — LUT Value
0x640 PAR_VPAC_VISS0__S_VBUSP__K3_GLBCE_TOP__CFG__GLBCE_REGS_GLBCE_WDR_GAMMA_LUT_219 reset 0xDB00
  [15:0] VAL — LUT Value
0x644 PAR_VPAC_VISS0__S_VBUSP__K3_GLBCE_TOP__CFG__GLBCE_REGS_GLBCE_WDR_GAMMA_LUT_220 reset 0xDC00
  [15:0] VAL — LUT Value
0x648 PAR_VPAC_VISS0__S_VBUSP__K3_GLBCE_TOP__CFG__GLBCE_REGS_GLBCE_WDR_GAMMA_LUT_221 reset 0xDD00
  [15:0] VAL — LUT Value
0x64C PAR_VPAC_VISS0__S_VBUSP__K3_GLBCE_TOP__CFG__GLBCE_REGS_GLBCE_WDR_GAMMA_LUT_222 reset 0xDE00
  [15:0] VAL — LUT Value
0x650 PAR_VPAC_VISS0__S_VBUSP__K3_GLBCE_TOP__CFG__GLBCE_REGS_GLBCE_WDR_GAMMA_LUT_223 reset 0xDF00
  [15:0] VAL — LUT Value
0x654 PAR_VPAC_VISS0__S_VBUSP__K3_GLBCE_TOP__CFG__GLBCE_REGS_GLBCE_WDR_GAMMA_LUT_224 reset 0xE000
  [15:0] VAL — LUT Value
0x658 PAR_VPAC_VISS0__S_VBUSP__K3_GLBCE_TOP__CFG__GLBCE_REGS_GLBCE_WDR_GAMMA_LUT_225 reset 0xE100
  [15:0] VAL — LUT Value
0x65C PAR_VPAC_VISS0__S_VBUSP__K3_GLBCE_TOP__CFG__GLBCE_REGS_GLBCE_WDR_GAMMA_LUT_226 reset 0xE200
  [15:0] VAL — LUT Value
0x660 PAR_VPAC_VISS0__S_VBUSP__K3_GLBCE_TOP__CFG__GLBCE_REGS_GLBCE_WDR_GAMMA_LUT_227 reset 0xE300
  [15:0] VAL — LUT Value
0x664 PAR_VPAC_VISS0__S_VBUSP__K3_GLBCE_TOP__CFG__GLBCE_REGS_GLBCE_WDR_GAMMA_LUT_228 reset 0xE400
  [15:0] VAL — LUT Value
0x668 PAR_VPAC_VISS0__S_VBUSP__K3_GLBCE_TOP__CFG__GLBCE_REGS_GLBCE_WDR_GAMMA_LUT_229 reset 0xE500
  [15:0] VAL — LUT Value
0x66C PAR_VPAC_VISS0__S_VBUSP__K3_GLBCE_TOP__CFG__GLBCE_REGS_GLBCE_WDR_GAMMA_LUT_230 reset 0xE600
  [15:0] VAL — LUT Value
0x670 PAR_VPAC_VISS0__S_VBUSP__K3_GLBCE_TOP__CFG__GLBCE_REGS_GLBCE_WDR_GAMMA_LUT_231 reset 0xE700
  [15:0] VAL — LUT Value
0x674 PAR_VPAC_VISS0__S_VBUSP__K3_GLBCE_TOP__CFG__GLBCE_REGS_GLBCE_WDR_GAMMA_LUT_232 reset 0xE800
  [15:0] VAL — LUT Value
0x678 PAR_VPAC_VISS0__S_VBUSP__K3_GLBCE_TOP__CFG__GLBCE_REGS_GLBCE_WDR_GAMMA_LUT_233 reset 0xE900
  [15:0] VAL — LUT Value
0x67C PAR_VPAC_VISS0__S_VBUSP__K3_GLBCE_TOP__CFG__GLBCE_REGS_GLBCE_WDR_GAMMA_LUT_234 reset 0xEA00
  [15:0] VAL — LUT Value
0x680 PAR_VPAC_VISS0__S_VBUSP__K3_GLBCE_TOP__CFG__GLBCE_REGS_GLBCE_WDR_GAMMA_LUT_235 reset 0xEB00
  [15:0] VAL — LUT Value
0x684 PAR_VPAC_VISS0__S_VBUSP__K3_GLBCE_TOP__CFG__GLBCE_REGS_GLBCE_WDR_GAMMA_LUT_236 reset 0xEC00
  [15:0] VAL — LUT Value
0x688 PAR_VPAC_VISS0__S_VBUSP__K3_GLBCE_TOP__CFG__GLBCE_REGS_GLBCE_WDR_GAMMA_LUT_237 reset 0xED00
  [15:0] VAL — LUT Value
0x68C PAR_VPAC_VISS0__S_VBUSP__K3_GLBCE_TOP__CFG__GLBCE_REGS_GLBCE_WDR_GAMMA_LUT_238 reset 0xEE00
  [15:0] VAL — LUT Value
0x690 PAR_VPAC_VISS0__S_VBUSP__K3_GLBCE_TOP__CFG__GLBCE_REGS_GLBCE_WDR_GAMMA_LUT_239 reset 0xEF00
  [15:0] VAL — LUT Value
0x694 PAR_VPAC_VISS0__S_VBUSP__K3_GLBCE_TOP__CFG__GLBCE_REGS_GLBCE_WDR_GAMMA_LUT_240 reset 0xF000
  [15:0] VAL — LUT Value
0x698 PAR_VPAC_VISS0__S_VBUSP__K3_GLBCE_TOP__CFG__GLBCE_REGS_GLBCE_WDR_GAMMA_LUT_241 reset 0xF100
  [15:0] VAL — LUT Value
0x69C PAR_VPAC_VISS0__S_VBUSP__K3_GLBCE_TOP__CFG__GLBCE_REGS_GLBCE_WDR_GAMMA_LUT_242 reset 0xF200
  [15:0] VAL — LUT Value
0x6A0 PAR_VPAC_VISS0__S_VBUSP__K3_GLBCE_TOP__CFG__GLBCE_REGS_GLBCE_WDR_GAMMA_LUT_243 reset 0xF300
  [15:0] VAL — LUT Value
0x6A4 PAR_VPAC_VISS0__S_VBUSP__K3_GLBCE_TOP__CFG__GLBCE_REGS_GLBCE_WDR_GAMMA_LUT_244 reset 0xF400
  [15:0] VAL — LUT Value
0x6A8 PAR_VPAC_VISS0__S_VBUSP__K3_GLBCE_TOP__CFG__GLBCE_REGS_GLBCE_WDR_GAMMA_LUT_245 reset 0xF500
  [15:0] VAL — LUT Value
0x6AC PAR_VPAC_VISS0__S_VBUSP__K3_GLBCE_TOP__CFG__GLBCE_REGS_GLBCE_WDR_GAMMA_LUT_246 reset 0xF600
  [15:0] VAL — LUT Value
0x6B0 PAR_VPAC_VISS0__S_VBUSP__K3_GLBCE_TOP__CFG__GLBCE_REGS_GLBCE_WDR_GAMMA_LUT_247 reset 0xF700
  [15:0] VAL — LUT Value
0x6B4 PAR_VPAC_VISS0__S_VBUSP__K3_GLBCE_TOP__CFG__GLBCE_REGS_GLBCE_WDR_GAMMA_LUT_248 reset 0xF800
  [15:0] VAL — LUT Value
0x6B8 PAR_VPAC_VISS0__S_VBUSP__K3_GLBCE_TOP__CFG__GLBCE_REGS_GLBCE_WDR_GAMMA_LUT_249 reset 0xF900
  [15:0] VAL — LUT Value
0x6BC PAR_VPAC_VISS0__S_VBUSP__K3_GLBCE_TOP__CFG__GLBCE_REGS_GLBCE_WDR_GAMMA_LUT_250 reset 0xFA00
  [15:0] VAL — LUT Value
0x6C0 PAR_VPAC_VISS0__S_VBUSP__K3_GLBCE_TOP__CFG__GLBCE_REGS_GLBCE_WDR_GAMMA_LUT_251 reset 0xFB00
  [15:0] VAL — LUT Value
0x6C4 PAR_VPAC_VISS0__S_VBUSP__K3_GLBCE_TOP__CFG__GLBCE_REGS_GLBCE_WDR_GAMMA_LUT_252 reset 0xFC00
  [15:0] VAL — LUT Value
0x6C8 PAR_VPAC_VISS0__S_VBUSP__K3_GLBCE_TOP__CFG__GLBCE_REGS_GLBCE_WDR_GAMMA_LUT_253 reset 0xFD00
  [15:0] VAL — LUT Value
0x6CC PAR_VPAC_VISS0__S_VBUSP__K3_GLBCE_TOP__CFG__GLBCE_REGS_GLBCE_WDR_GAMMA_LUT_254 reset 0xFE00
  [15:0] VAL — LUT Value
0x6D0 PAR_VPAC_VISS0__S_VBUSP__K3_GLBCE_TOP__CFG__GLBCE_REGS_GLBCE_WDR_GAMMA_LUT_255 reset 0xFF00
  [15:0] VAL — LUT Value
0x6D4 PAR_VPAC_VISS0__S_VBUSP__K3_GLBCE_TOP__CFG__GLBCE_REGS_GLBCE_WDR_GAMMA_LUT_256 reset 0xFFFF
  [15:0] VAL — LUT Value
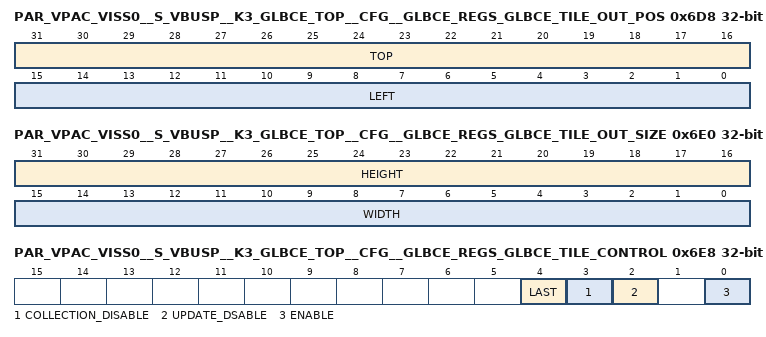
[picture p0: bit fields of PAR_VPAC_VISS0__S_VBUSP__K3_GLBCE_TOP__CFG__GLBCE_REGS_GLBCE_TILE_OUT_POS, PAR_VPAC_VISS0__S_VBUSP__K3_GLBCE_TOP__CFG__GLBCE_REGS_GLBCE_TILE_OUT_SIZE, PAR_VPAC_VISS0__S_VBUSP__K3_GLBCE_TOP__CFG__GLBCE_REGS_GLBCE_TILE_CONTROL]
0x6D8 PAR_VPAC_VISS0__S_VBUSP__K3_GLBCE_TOP__CFG__GLBCE_REGS_GLBCE_TILE_OUT_POS
  [31:16] TOP — Tile Top position
  [15:0] LEFT — Tile Left position
0x6E0 PAR_VPAC_VISS0__S_VBUSP__K3_GLBCE_TOP__CFG__GLBCE_REGS_GLBCE_TILE_OUT_SIZE
  [31:16] HEIGHT — Tile Height
  [15:0] WIDTH — Tile Width
0x6E8 PAR_VPAC_VISS0__S_VBUSP__K3_GLBCE_TOP__CFG__GLBCE_REGS_GLBCE_TILE_CONTROL
  [4] LAST — Last time
  [3] COLLECTION_DISABLE — Statistics collection disable
  [2] UPDATE_DSABLE — Statistics update disable
  [0] ENABLE — Tile processing Enable
0x6EC PAR_VPAC_VISS0__S_VBUSP__K3_GLBCE_TOP__CFG__GLBCE_REGS_GLBCE_OUTPUT_FLAGS ro
  [15:0] TILE_STATUS
